# PY32MD410xx register map
Vendor: Puya; Series: PY32M; File version: 1.0.0
CPU: CM0+ r0p1, little endian, no MPU, no FPU, 4 interrupt priority bits
Registers are 32-bit, read-write, reset 0x0 unless marked. A register's access mark holds for its fields unless they carry their own. Offsets are from the block's base; [hi:lo] are bit positions.

## SPI1 — Serial peripheral interface
Base 0x40013000
Same registers: SPI2 0x40003800
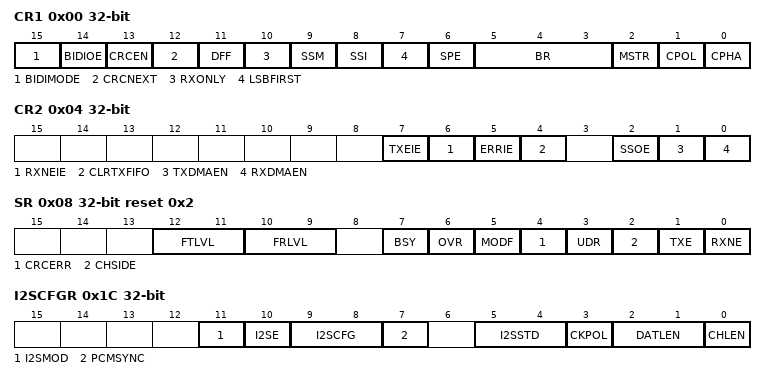
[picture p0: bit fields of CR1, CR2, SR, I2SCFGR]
0x00 CR1 — control register 1
  [15] BIDIMODE — Bidirectional data mode enable
  [14] BIDIOE — Output enable in bidirectional mode
  [13] CRCEN — Hardware CRC calculation enable
  [12] CRCNEXT — Transmit CRC next
  [11] DFF — Data frame format
  [10] RXONLY — Receive only
  [9] SSM — Software slave management
  [8] SSI — Internal slave selection
  [7] LSBFIRST — Frame format
  [6] SPE — SPI enable
  [5:3] BR — Baud rate control
    1=0; 2=1; 4=2
  [2] MSTR — Master selection
  [1] CPOL — Clock polarity
  [0] CPHA — Clock phase
0x04 CR2 — control register 2
  [7] TXEIE — Tx buffer empty interrupt enable
  [6] RXNEIE — RX buffer not empty interrupt enable
  [5] ERRIE — Error interrupt enable
  [4] CLRTXFIFO — Clear TXFIFO
  [2] SSOE — SS output enable
  [1] TXDMAEN — Tx buffer DMA enable
  [0] RXDMAEN — Rx buffer DMA enable
0x08 SR reset 0x2 — status register
  [12:11] FTLVL ro — FIFO transmission level
    1=0; 2=1
  [10:9] FRLVL ro — FIFO reception level
    1=0; 2=1
  [7] BSY ro — Busy flag
  [6] OVR ro — Overrun flag
  [5] MODF ro — Mode fault
  [4] CRCERR ro — CRC error flag
  [3] UDR ro — Underflow flag
  [2] CHSIDE ro — Channel control
  [1] TXE ro — Transmit buffer empty
  [0] RXNE ro — Receive buffer not empty
0x0C DR — data register
  [15:0] DR — Data register
0x10 CRCPR — CRC polynomial register
  [15:0] CRCPOLY
0x14 RXCRC
  [15:0] RXCRC
0x18 TXCRC
  [15:0] TXCRC
0x1C I2SCFGR — I2S Configuration register
  [11] I2SMOD — I2S mode selection
  [10] I2SE — I2S enable
  [9:8] I2SCFG — I2S configuration mode
    1=0; 2=1
  [7] PCMSYNC — PCM frame synchronization
  [5:4] I2SSTD — I2S standard selection
    1=0; 2=1
  [3] CKPOL — Steady state clock polarity
  [2:1] DATLEN — Data length to be transferred
    1=0; 2=1
  [0] CHLEN — Channel length
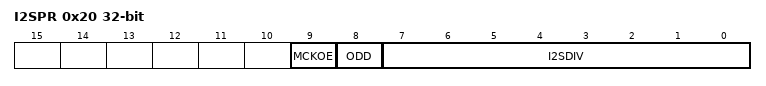
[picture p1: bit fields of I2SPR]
0x20 I2SPR — I2S prescaler register
  [9] MCKOE — Master clock output enable
  [8] ODD — Odd factor for the prescaler
  [7:0] I2SDIV — I2S linear prescaler

## SYSCFG — System configuration controller
Base 0x40010000
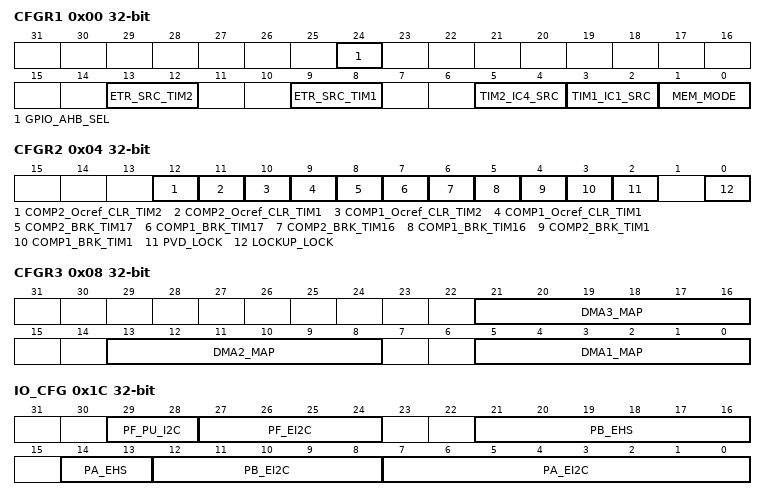
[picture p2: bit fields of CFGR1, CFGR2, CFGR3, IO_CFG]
0x00 CFGR1 — SYSCFG configuration register1
  [24] GPIO_AHB_SEL
  [13:12] ETR_SRC_TIM2
    1=0; 2=1
  [9:8] ETR_SRC_TIM1
    1=0; 2=1
  [5:4] TIM2_IC4_SRC
    1=0; 2=1
  [3:2] TIM1_IC1_SRC
    1=0; 2=1
  [1:0] MEM_MODE — Memory mapping selection bits
    1=0; 2=1
0x04 CFGR2 — SYSCFG configuration register2
  [12] COMP2_Ocref_CLR_TIM2
  [11] COMP2_Ocref_CLR_TIM1
  [10] COMP1_Ocref_CLR_TIM2
  [9] COMP1_Ocref_CLR_TIM1
  [8] COMP2_BRK_TIM17 — COMP2 is enable to input of TIM17 break
  [7] COMP1_BRK_TIM17 — COMP1 is enable to input of TIM17 break
  [6] COMP2_BRK_TIM16 — COMP2 is enable to input of TIM16 break
  [5] COMP1_BRK_TIM16 — COMP1 is enable to input of TIM16 break
  [4] COMP2_BRK_TIM1 — COMP2 is enable to input of TIM1 break
  [3] COMP1_BRK_TIM1 — COMP1 is enable to input of TIM1 break
  [2] PVD_LOCK — PVD lock enable bit
  [0] LOCKUP_LOCK — Cortex-M0+ LOCKUP bit enable bit
0x08 CFGR3 — SYSCFG configuration register3
  [all] fields
    1=0; 2=1; 4=2; 8=3; 16=4; 32=5
  [21:16] DMA3_MAP — DMA channel3 requeset selection
  [13:8] DMA2_MAP — DMA channel2 requeset selection
  [5:0] DMA1_MAP — DMA channel1 requeset selection
0x10 PA_ENS — GPIOA noise filter enable register
  [15:0] PA_ENS — Noise filter enable, active high
0x14 PB_ENS — GPIOB noise filter enable register
  [15:0] PB_ENS — Noise filter enable, active high
0x18 PF_ENS — GPIOF noise filter enable register
  [15:0] PF_ENS — Noise filter enable, active high
0x1C IO_CFG — I2C type IO configure register
  [29:28] PF_PU_I2C, [27:24] PF_EI2C, [21:16] PB_EHS, [14:13] PA_EHS, [12:8] PB_EI2C, [7:0] PA_EI2C
0x20 PA_ANA2EN — GPIOA Analog2 enable register
  [15:0] PA_ANA2EN — IO PORTA PAD_ANA2 enable
0x24 PB_ANA2EN — GPIOB Analog2 enable register
  [15:0] PB_ANA2EN — IO PORTB PAD_ANA2 enable
0x28 PF_ANA2EN — GPIOF Analog2 enable register
  [15:0] PF_ANA2EN — IO PORTF PAD_ANA2 enable
